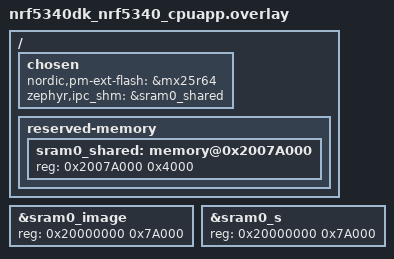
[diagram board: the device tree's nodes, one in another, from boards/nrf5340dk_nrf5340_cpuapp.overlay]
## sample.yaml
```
sample:
  name: BLE nrf dfu rpc example
  description: secondary slot on external QSPI flash. Both BT host and controller run on network core.
tests:
  samples.bluetooth.peripheral_uart:
    build_only: true
    build_on_all: true
    platform_allow: nrf5340dk_nrf5340_cpuapp
    tags: bluetooth ci_build
```

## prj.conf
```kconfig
#
# Copyright (c) 2018 Nordic Semiconductor
#
# SPDX-License-Identifier: LicenseRef-Nordic-5-Clause
#

CONFIG_GPIO=y

# Make sure printk is not printing to the UART console
CONFIG_CONSOLE=y
CONFIG_UART_CONSOLE=y

CONFIG_HEAP_MEM_POOL_SIZE=12288

CONFIG_FLASH=y
CONFIG_FLASH_PAGE_LAYOUT=y
CONFIG_FLASH_MAP=y
CONFIG_NVS=y
CONFIG_MPU_ALLOW_FLASH_WRITE=y

# Enable DK LED and Buttons library
CONFIG_DK_LIBRARY=y

# This example requires more workqueue stack
CONFIG_SYSTEM_WORKQUEUE_STACK_SIZE=2048

# Config logger
CONFIG_LOG=y
# CONFIG_USE_SEGGER_RTT=y
# CONFIG_LOG_BACKEND_RTT=y
# CONFIG_LOG_BACKEND_UART=n
# CONFIG_LOG_DEFAULT_LEVEL=4

CONFIG_ASSERT=y
# CONFIG_ASSERT_LEVEL=2

CONFIG_SERIAL=y
CONFIG_UART_ASYNC_API=y
CONFIG_UART_0_ASYNC=y
CONFIG_NRFX_UARTE0=y
CONFIG_UART_0_NRF_HW_ASYNC=y
CONFIG_UART_0_NRF_HW_ASYNC_TIMER=1


CONFIG_NRF_RPC=y
CONFIG_NRF_RPC_CBOR=y
CONFIG_NRF_RPC_THREAD_STACK_SIZE=4096

CONFIG_NRF_DFU=y
CONFIG_NRF_DFU_RPC_APP=y
# CONFIG_NRF_DFU_LOG_LEVEL=3
CONFIG_BOOTLOADER_MCUBOOT=y
CONFIG_IMG_MANAGER=y
CONFIG_MCUBOOT_IMG_MANAGER=y
CONFIG_IMG_BLOCK_BUF_SIZE=4096

CONFIG_BLE_NETWORK_CORE=y
CONFIG_NRF53_UPGRADE_NETWORK_CORE=y
CONFIG_BOARD_ENABLE_CPUNET=y

## secondary slot on external Flash ##
CONFIG_PM_PARTITION_SIZE_SETTINGS_STORAGE=0x4000
CONFIG_NORDIC_QSPI_NOR=y
CONFIG_NORDIC_QSPI_NOR_FLASH_LAYOUT_PAGE_SIZE=4096
CONFIG_NORDIC_QSPI_NOR_STACK_WRITE_BUFFER_SIZE=16
CONFIG_STREAM_FLASH=y
CONFIG_STREAM_FLASH_ERASE=y
```

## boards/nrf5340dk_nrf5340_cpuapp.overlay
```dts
/* overlay file for app core */

/ {
	chosen {
		nordic,pm-ext-flash = &mx25r64;
	};
};

/* adjust the RAM size of application image */
&sram0_image{
	reg = < 0x20000000 0x7A000 >;
};

&sram0_s{
	reg = < 0x20000000 0x7A000 >;
};

/delete-node/ &sram0_shared;

/ {
	chosen {
		/* shared memory reserved for the inter-processor communication */
		zephyr,ipc_shm = &sram0_shared;
	};

	reserved-memory {
		#address-cells = <1>;
		#size-cells = <1>;
		ranges;	
		sram0_shared: memory@0x2007A000 {
			/* SRAM allocated to shared memory */
			reg = <0x2007A000 0x4000>;
		};
	};
};
```

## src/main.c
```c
/*
 * Copyright (c) 2018 Nordic Semiconductor ASA
 *
 * SPDX-License-Identifier: LicenseRef-Nordic-5-Clause
 */

/** @file
 *  @brief Nordic UART Bridge Service (NUS) sample
 */

#include <zephyr/types.h>
#include <zephyr/kernel.h>
#include <zephyr/drivers/uart.h>

#include <zephyr/device.h>
#include <soc.h>

#include <dk_buttons_and_leds.h>

#include <zephyr/settings/settings.h>

#include <stdio.h>

#include "nrf_dfu_settings.h"
#include "nrf_dfu.h"

#include "uart_hs.h"
#include <zephyr/sys/reboot.h>
#include "nrf_dfu.h"
#include "nrf_dfu_validation.h"
#include <drivers/nrfx_errors.h>
#include <zephyr/logging/log.h>
#include <zephyr/logging/log_ctrl.h>

#define LOG_MODULE_NAME main
LOG_MODULE_REGISTER(LOG_MODULE_NAME);

#define RUN_STATUS_LED DK_LED1
#define RUN_LED_BLINK_INTERVAL 1000


#define UART_BUF_SIZE CONFIG_BT_NUS_UART_BUFFER_SIZE
#define UART_WAIT_FOR_BUF_DELAY K_MSEC(50)
#define UART_WAIT_FOR_RX 10000

static void configure_gpio(void)
{
	int err;

	err = dk_leds_init();
	if (err) {
		LOG_ERR("Cannot init LEDs (err: %d)", err);
	}
}

/**@brief Function for handling DFU events.
 */
static void dfu_observer(nrf_dfu_evt_type_t evt_type)
{
    switch (evt_type)
    {
        case NRF_DFU_EVT_DFU_STARTED:
        case NRF_DFU_EVT_OBJECT_RECEIVED:

            break;
        case NRF_DFU_EVT_DFU_COMPLETED:
        case NRF_DFU_EVT_DFU_ABORTED:
			LOG_INF("resetting...");
			while(log_process());
            sys_reboot(SYS_REBOOT_WARM);
            break;
        case NRF_DFU_EVT_TRANSPORT_DEACTIVATED:
            // Reset the internal state of the DFU settings to the last stored state.
			LOG_INF("NRF_DFU_EVT_TRANSPORT_DEACTIVATED");
            nrf_dfu_settings_reinit();
            break;
        default:
            break;
    }

}

int dfu_init(void)
{
    int ret_val;

    ret_val = nrf_dfu_settings_init(true);
    if (ret_val != NRF_SUCCESS)
	{
		LOG_WRN("dfu settings init err %d", ret_val);
	}

    ret_val = nrf_dfu_init(dfu_observer);
    if (ret_val != NRF_SUCCESS)
	{
		LOG_WRN("dfu init err %d", ret_val);
	}

    return ret_val;
}

void uart_rx_cb(uint8_t *data, uint16_t len)
{
	// if (bt_nus_send(NULL,data, len)) {
	// 	LOG_WRN("Failed to send data over BLE connection");
	// }	
}
static void error(void)
{
	dk_set_leds_state(DK_ALL_LEDS_MSK, DK_NO_LEDS_MSK);

	while (true) {
		/* Spin for ever */
		k_sleep(K_MSEC(1000));
	}
}

void main(void)
{
	int blink_status = 0;
	int err = 0;

	LOG_INF("### nRF5 SDK DFU example %s %s\n", __TIME__, __DATE__);

	configure_gpio();

	err = uart_init(uart_rx_cb);
	if (err) {
		error();
	}

	err = dfu_init();
	if (err) {
		LOG_ERR("dfu service init err %d", err);
		return;
	}

	for (;;) {
		dk_set_led(RUN_STATUS_LED, (++blink_status) % 2);		
		uart_receive();
	}
}
```

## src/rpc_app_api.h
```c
/*
 * Copyright (c) 2020 Nordic Semiconductor ASA
 *
 * SPDX-License-Identifier: Apache-2.0
 */

#ifndef RPC_APP_API_H_
#define RPC_APP_API_H_

#include <zephyr/types.h>


/**
 * @file
 * @defgroup entropy_ser Entropy driver serialization
 * @{
 * @brief Entropy serialization API.
 */

#ifdef __cplusplus
extern "C" {
#endif

int app2net_send_nus(uint8_t *data, uint16_t len);
int rpc_app2net_send(int32_t type, uint8_t *buffer, int32_t length);
int net2app_receive(int type, uint8_t *data, size_t len);
bool is_ble_connected(void);

#ifdef __cplusplus
}
#endif

/**
 * @}
 */

#endif /* RPC_APP_API_H_ */
```

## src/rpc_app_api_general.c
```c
/*
 * Copyright (c) 2020 Nordic Semiconductor ASA
 *
 * SPDX-License-Identifier: LicenseRef-BSD-5-Clause-Nordic
 */
#include <errno.h>
#include <zephyr/init.h>

#include <tinycbor/cbor.h>

#include <nrf_rpc_cbor.h>

#include "common_ids.h"
#include <zephyr/logging/log.h>
#include "rpc_app_api.h"

#define LOG_MODULE_NAME rpc_app_api_general
LOG_MODULE_REGISTER(LOG_MODULE_NAME);


#define CBOR_BUF_SIZE 16


NRF_RPC_GROUP_DEFINE(rpc_api, "rpc_api", NULL, NULL, NULL);

static void rsp_error_code_handle(CborValue *value, void *handler_data)
{
	CborError cbor_err;

	if (!cbor_value_is_integer(value)) {
		*(int *)handler_data = -NRF_EINVAL;
	}

	cbor_err = cbor_value_get_int(value, (int *)handler_data);
	if (cbor_err != CborNoError) {
		*(int *)handler_data = -NRF_EINVAL;
	}
}

int rpc_app2net_send(int type, uint8_t *buffer, size_t length)
{
	int err;
	int result;
	struct nrf_rpc_cbor_ctx ctx;

	if (!buffer || length < 1) {
		return -NRF_EINVAL;
	}	

	NRF_RPC_CBOR_ALLOC(ctx, CBOR_BUF_SIZE + length);

	
	cbor_encode_int(&ctx.encoder, type);

	cbor_encode_int(&ctx.encoder, length);

	cbor_encode_byte_string(&ctx.encoder, buffer, length);	

	err = nrf_rpc_cbor_cmd(&rpc_api, RPC_COMMAND_APP_SEND, &ctx,
			       rsp_error_code_handle, &result);
	if (err < 0) {
		return err;
	}

	return result;
}

static void rpc_net2app_send(CborValue *packet, void *handler_data)
{	
	CborError cbor_err;
	int err;
	size_t length;
	uint8_t buf[256];
	int type;

	err = cbor_value_get_int(packet, &type);
	if (err != CborNoError) {
		goto cbor_error_exit;
	}

	err = cbor_value_advance(packet);
	if (err != CborNoError) {
		goto cbor_error_exit;
	}

	err = cbor_value_get_int(packet, &length);
	if (err != CborNoError) {
		goto cbor_error_exit;
	}

	err = cbor_value_advance(packet);
	if (err != CborNoError) {
		goto cbor_error_exit;
	}	

	length = 256;
	cbor_err = cbor_value_copy_byte_string(packet, buf, &length,
					       NULL);
	if (cbor_err != CborNoError || length < 0 || length > sizeof(buf)) {
		goto cbor_error_exit;	
	}

	nrf_rpc_cbor_decoding_done(packet);

	err = net2app_receive(type, buf, length);
	
	struct nrf_rpc_cbor_ctx ctx;
	NRF_RPC_CBOR_ALLOC(ctx, CBOR_BUF_SIZE);
	cbor_encode_int(&ctx.encoder, err);	
	nrf_rpc_cbor_rsp_no_err(&ctx);
	return;

cbor_error_exit:
	nrf_rpc_cbor_decoding_done(packet);	
}


NRF_RPC_CBOR_CMD_DECODER(rpc_api, rpc_net2app_send_name,
			 RPC_COMMAND_NET_SEND,
			 rpc_net2app_send, NULL);

static void err_handler(const struct nrf_rpc_err_report *report)
{
	printk("nRF RPC error %d ocurred. See nRF RPC logs for more details.",
	       report->code);
	k_oops();
}


static int serialization_init(const struct device *dev)
{
	ARG_UNUSED(dev);

	int err;	

	err = nrf_rpc_init(err_handler);
	if (err) {
		return -NRF_EINVAL;
	}

	return 0;
}


SYS_INIT(serialization_init, POST_KERNEL, CONFIG_APPLICATION_INIT_PRIORITY);
```

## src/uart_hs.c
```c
/*
 * Copyright (c) 2020 Nordic Semiconductor ASA
 *
 * SPDX-License-Identifier: LicenseRef-BSD-5-Clause-Nordic
 */

#include <zephyr.h>
#include <device.h>
#include <devicetree.h>
#include <drivers/gpio.h>
#include <stdio.h>
#include <logging/log.h>
#include <drivers/uart.h>
#include "uart_hs.h"


#define LOG_MODULE_NAME uart_hs
LOG_MODULE_REGISTER(LOG_MODULE_NAME);

#define UART_DEVICE_NAME         DT_LABEL(DT_NODELABEL(uart0))

#define UART_BUF_SIZE 255
#define UART_WAIT_FOR_BUF_DELAY K_MSEC(100)
#define UART_WAIT_FOR_RX 10000

static const struct device *uart;
static rx_callback_t rx_callback;

struct uart_data_t {
	void *fifo_reserved;
	uint8_t data[UART_BUF_SIZE];
	uint16_t len;
};

static uint8_t uart_rx_buf[2][UART_BUF_SIZE];
static uint8_t *next_buf = uart_rx_buf[1];

static K_FIFO_DEFINE(fifo_uart_tx_data);
static K_FIFO_DEFINE(fifo_uart_rx_data);


static void uart_cb(const struct device *dev, struct uart_event *evt, void *user_data)
{
	ARG_UNUSED(dev);
	int err;

	switch (evt->type) {
	case UART_TX_DONE:
	{
		struct uart_data_t *buf;
		struct uart_data_t *buf2;
		
		buf = CONTAINER_OF(evt->data.tx.buf, struct uart_data_t,  data);		
		LOG_INF("UART_TX_DONE %d", evt->data.tx.len);
		k_free(buf);

		buf2 = k_fifo_get(&fifo_uart_tx_data, K_NO_WAIT);
		if (!buf2) {
			return;
		}

		if (uart_tx(uart, buf2->data, buf2->len, SYS_FOREVER_MS)) {
			LOG_WRN("uart_tx fail @ cb");
		}
	}
		break;

	case UART_RX_RDY:
	{
		struct uart_data_t *buf = k_malloc(sizeof(struct uart_data_t));
		memcpy(buf->data, &evt->data.rx.buf[evt->data.rx.offset], evt->data.rx.len);	
		buf->len = evt->data.rx.len;		
		k_fifo_put(&fifo_uart_rx_data, buf);
		LOG_INF("UART_RX_RDY %d", buf->len);
	}
		break;

	case UART_RX_DISABLED:
		LOG_INF("UART_RX_DISABLED");
		err = uart_rx_enable(uart, uart_rx_buf[0], sizeof(uart_rx_buf[0]), UART_WAIT_FOR_RX);
		if (err) {
			LOG_ERR("UART RX enable failed: %d", err);			
		}
		break;

	case UART_RX_BUF_REQUEST:
		err = uart_rx_buf_rsp(uart, next_buf,
			sizeof(uart_rx_buf[0]));
		if (err) {
			LOG_WRN("UART RX buf rsp: %d", err);
		}		
		break;

	case UART_RX_BUF_RELEASED:
		LOG_INF("UART_RX_BUF_RELEASED");
		next_buf = evt->data.rx_buf.buf;
		break;

	case UART_TX_ABORTED:
		LOG_INF("UART_TX_ABORTED");
		break;

	default:
		break;
	}
}

int uart_init(rx_callback_t cb)
{
	int err;
	
	uart = device_get_binding(UART_DEVICE_NAME);
	if (!uart) {
		return -ENXIO;
	}

	err = uart_callback_set(uart, uart_cb, NULL);
	if (err) {
		return err;
	}

	rx_callback = cb;

	return uart_rx_enable(uart, uart_rx_buf[0], sizeof(uart_rx_buf[0]), UART_WAIT_FOR_RX);

}

int uart_send(const uint8_t *buf, uint16_t len)
{
	int err;
	struct uart_data_t *tx = k_malloc(sizeof(*tx));

	if (!tx) {
		LOG_WRN("Not able to allocate UART send data buffer");
		return -ENOMEM; 
	}

	memcpy(tx->data, buf, len);	
	tx->len = len;
	err = uart_tx(uart, tx->data, tx->len, SYS_FOREVER_MS);
	if (err) {
		LOG_WRN("buffer uart tx data for later retry");
		k_fifo_put(&fifo_uart_tx_data, tx);
	}
	return err;		
}

void uart_receive()
{
	/* Wait indefinitely*/
	struct uart_data_t *buf = k_fifo_get(&fifo_uart_rx_data,
							K_FOREVER);
	rx_callback(buf->data,buf->len);							
	k_free(buf);		
}

// void uart_thread(void)
// {    
// 	static uint32_t uart_len;	

// 	LOG_INF("**high speed UART example");
// 	uart_init();

// 	while (1) {

// 		/* Send the UART data back to the peer. Wait indefinitely*/
// 		struct uart_data_t *buf = k_fifo_get(&fifo_uart_rx_data,
// 						     K_FOREVER);

// 		uart_send(buf->data,buf->len);

// 		uart_len += buf->len;
// 		LOG_INF("uart rx total len %d and %d", uart_len, buf->len);
// 		k_free(buf);					
// 	}
// }
```
